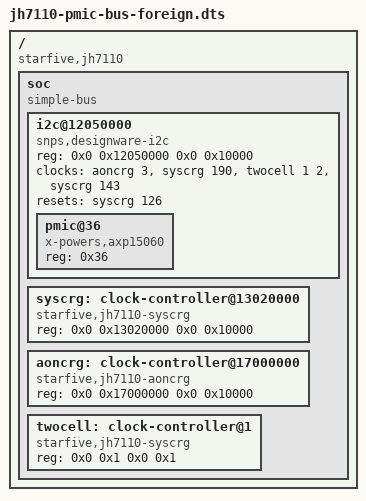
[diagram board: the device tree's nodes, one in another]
/dts-v1/;

/*
 * A **hostile** PMIC bus, not any real board (milestone 592
 * (radon's cold reboot dies in OpenSBI's PMIC write), provisional). Every specifier here is
 * one `pmic_bus` must refuse to turn into a store:
 * - `<&aoncrg 3>`: a real clock controller, the wrong domain (AON clock 3 is not SYS clock 3);
 * - `<&syscrg 190>`: the right provider, one past SYSCLK_END;
 * - `<&syscrg 126>` in `resets`: one past SYSRST_END;
 * - `<&twocell 1 2>`: a provider with two cells per specifier, after which the eight-byte stride
 *   is wrong and nothing else in that list can be read.
 * With nothing usable left, the plan falls back to the constant and says so.
 *
 * Regenerate with:
 *
 *     dtc -I dts -O dtb -o crates/machine_discovery/tests/fixtures/jh7110-pmic-bus-foreign.dtb \
 *                          crates/machine_discovery/tests/fixtures/jh7110-pmic-bus-foreign.dts
 */

/ {
	#address-cells = <2>;
	#size-cells = <2>;
	compatible = "starfive,jh7110";

	soc {
		compatible = "simple-bus";
		#address-cells = <2>;
		#size-cells = <2>;
		ranges;

		i2c@12050000 {
			compatible = "snps,designware-i2c";
			reg = <0x0 0x12050000 0x0 0x10000>;
			clocks = <&aoncrg 3>, <&syscrg 190>, <&twocell 1 2>, <&syscrg 143>;
			resets = <&syscrg 126>;
			#address-cells = <1>;
			#size-cells = <0>;

			pmic@36 {
				compatible = "x-powers,axp15060";
				reg = <0x36>;
			};
		};

		syscrg: clock-controller@13020000 {
			compatible = "starfive,jh7110-syscrg";
			reg = <0x0 0x13020000 0x0 0x10000>;
			#clock-cells = <1>;
			#reset-cells = <1>;
		};

		aoncrg: clock-controller@17000000 {
			compatible = "starfive,jh7110-aoncrg";
			reg = <0x0 0x17000000 0x0 0x10000>;
			#clock-cells = <1>;
			#reset-cells = <1>;
		};

		twocell: clock-controller@1 {
			compatible = "starfive,jh7110-syscrg";
			reg = <0x0 0x1 0x0 0x1>;
			#clock-cells = <2>;
		};
	};
};
